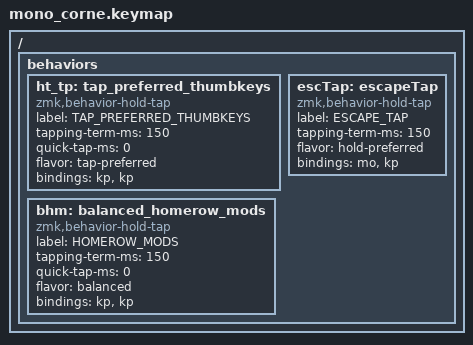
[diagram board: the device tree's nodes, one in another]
#include "base_36.keymap"

/ {
	behaviors {
		ht_tp: tap_preferred_thumbkeys {
			compatible = "zmk,behavior-hold-tap";
			label = "TAP_PREFERRED_THUMBKEYS";
			#binding-cells = <2>;
			tapping-term-ms = <150>;
			quick-tap-ms = <0>;
			flavor = "tap-preferred";
			bindings = <&kp>, <&kp>;
		};
		
        bhm: balanced_homerow_mods {
			compatible = "zmk,behavior-hold-tap";
			label = "HOMEROW_MODS";
			#binding-cells = <2>;
			tapping-term-ms = <150>;
			quick-tap-ms = <0>;
			flavor = "balanced";
			bindings = <&kp>, <&kp>;
		};
        
        escTap: escapeTap {
            compatible = "zmk,behavior-hold-tap";
            label = "ESCAPE_TAP";
            #binding-cells = <2>;
            tapping-term-ms = <150>;
            flavor = "hold-preferred";
            bindings = <&mo>, <&kp>;
        };
	};
};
